# MCXA133 register map
Vendor: nxp.com; File version: 1.0
CPU: CM33 r2p0, little endian, no MPU, no FPU, VTOR, 3 interrupt priority bits
Registers are 32-bit, read-write, reset 0x0 unless marked. A register's access mark holds for its fields unless they carry their own. Offsets are from the block's base; [hi:lo] are bit positions; 'fields as' and 'values as' point back to an identical list.

## SPC0 — SPC
Base 0x40090000
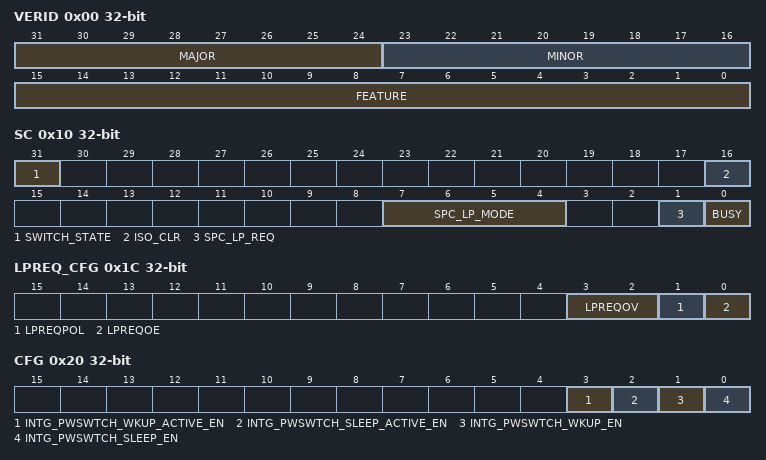
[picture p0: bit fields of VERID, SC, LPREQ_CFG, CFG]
0x00 VERID ro — Version ID
  [31:24] MAJOR — Major Version Number
  [23:16] MINOR — Minor Version Number
  [15:0] FEATURE — Feature Specification Number
    0=STANDARD (Standard features)
0x10 SC — Status Control
  [31] SWITCH_STATE ro — Power Switch State
    0=OFF; 1=ON
  [16] ISO_CLR write-1-clears — Isolation Clear Flags
  [7:4] SPC_LP_MODE ro — Power Domain Low-Power Mode Request
    0=MODE0 (Sleep mode with system clock running); 1=MODE1 (DSLEEP with system clock off); 2=MODE2 (PDOWN with system clock off); 8=MODE8 (DPDOWN with system clock off)
  [1] SPC_LP_REQ write-1-clears — SPC Power Mode Configuration Status Flag
    on read: 0=ACTIVE (SPC is in Active mode; the ACTIVE_CFG register has control); 1=LOW_POWER (All power domains requested low-power mode; SPC entered a low-power state; power-mode configuration based on the LP_CFG register)
  [0] BUSY ro — SPC Busy Status Flag
    0=BUSY_NO (Not busy); 1=BUSY_YES
0x1C LPREQ_CFG — Low-Power Request Configuration
  [3:2] LPREQOV — Low-Power Request Output Override
    0=FORCE_NO (Not forced); 2=FORCE_LOW (Forced low (ignore LPREQPOL settings)); 3=FORCE_HIGH (Forced high (ignore LPREQPOL settings))
  [1] LPREQPOL — Low-Power Request Output Pin Polarity Control
    0=HIGH; 1=LOW
  [0] LPREQOE — Low-Power Request Output Enable
    0=DISABLE; 1=ENABLE
0x20 CFG — SPC Configuration
  [all] fields
    0=DISABLE; 1=ENABLE
  [3] INTG_PWSWTCH_WKUP_ACTIVE_EN — Integrated Power Switch Wake-up Enable
  [2] INTG_PWSWTCH_SLEEP_ACTIVE_EN — Integrated Power Switch Active Enable
  [1] INTG_PWSWTCH_WKUP_EN — Integrated Power Switch Wake-up Enable
  [0] INTG_PWSWTCH_SLEEP_EN — Integrated Power Switch Sleep Enable
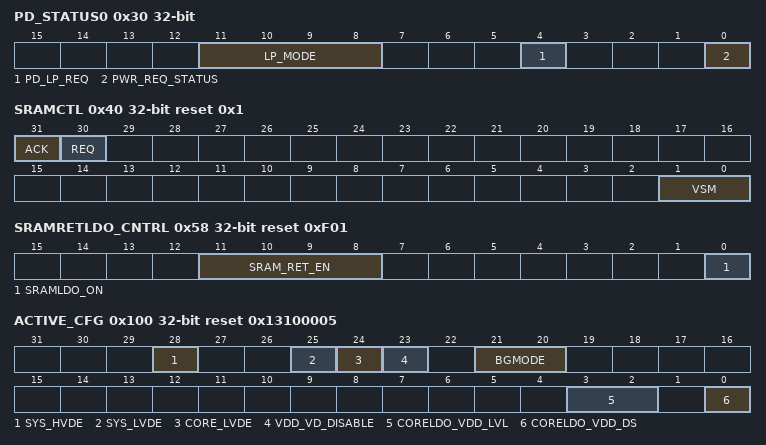
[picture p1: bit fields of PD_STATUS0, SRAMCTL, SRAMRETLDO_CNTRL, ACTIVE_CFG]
0x30 PD_STATUS0 — SPC Power Domain Mode Status
  [11:8] LP_MODE ro — Power Domain Low Power Mode Request
    0=MODE0 (SLEEP with system clock running); 1=MODE1 (DSLEEP with system clock off); 2=MODE2 (PDOWN with system clock off); 8=MODE8 (DPDOWN with system clock off)
  [4] PD_LP_REQ write-1-clears — Power Domain Low Power Request Flag
    0=REQ_NO (Did not request); 1=REQ_YES (Requested)
  [0] PWR_REQ_STATUS ro — Power Request Status Flag
    0=REQ_NO (Did not request); 1=REQ_YES (Requested)
0x40 SRAMCTL reset 0x1 — SRAM Control
  [31] ACK ro — SRAM Voltage Update Request Acknowledge
    0=ACK_NO (Not acknowledged); 1=ACK_YES (Acknowledged)
  [30] REQ — SRAM Voltage Update Request
    0=REQ_NO (Do not request); 1=REQ_YES (Request)
  [1:0] VSM — Voltage Select Margin
    1=1.0 V; 2=1.1 V; 3=SRAM configured for 1.2 V operation
0x54 SRAMRETLDO_REFTRIM reset 0x17 — SRAM Retention Reference Trim
  [4:0] REFTRIM — Reference Trim. Voltage range is around 0.48V - 0.85V. Trim step is 12 mV.
0x58 SRAMRETLDO_CNTRL reset 0xF01 — SRAM Retention LDO Control
  [11:8] SRAM_RET_EN — SRAM Retention
  [0] SRAMLDO_ON — SRAM LDO Regulator Enable
    0=DISABLE; 1=ENABLE
0x100 ACTIVE_CFG reset 0x13100005 — Active Power Mode Configuration
  [28] SYS_HVDE — System High-Voltage Detection Enable
    0=DISABLE; 1=ENABLE
  [25] SYS_LVDE — System Low-Voltage Detection Enable
    0=DISABLE; 1=ENABLE
  [24] CORE_LVDE — Core Low-Voltage Detection Enable
    0=DISABLE; 1=ENABLE
  [23] VDD_VD_DISABLE — VDD Voltage Detect Disable
    0=ENABLE; 1=DISABLE
  [21:20] BGMODE — Bandgap Mode
    0=Bandgap disabled; 1=Bandgap enabled, buffer disabled; 2=Bandgap enabled, buffer enabled
  [3:2] CORELDO_VDD_LVL — LDO_CORE VDD Regulator Voltage Level
    1=MID (Regulate to mid voltage (1.0 V)); 2=NORMAL (Regulate to normal voltage (1.1 V)); 3=OVER (Regulate to overdrive voltage (1.15 V))
  [0] CORELDO_VDD_DS — LDO_CORE VDD Drive Strength
    0=LOW; 1=NORMAL
0x104 ACTIVE_CFG1 reset 0x2 — Active Power Mode Configuration 1
  [31:0] SOC_CNTRL — Active Config Chip Control
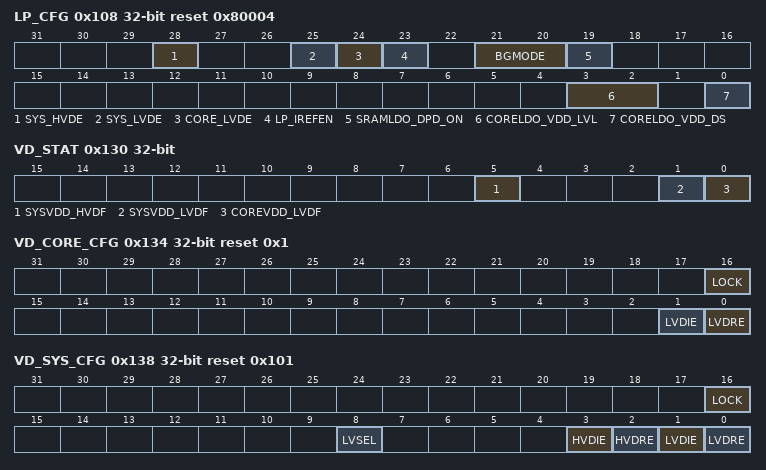
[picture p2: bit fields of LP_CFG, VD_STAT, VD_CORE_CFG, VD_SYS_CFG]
0x108 LP_CFG reset 0x80004 — Low-Power Mode Configuration
  [28] SYS_HVDE — System High Voltage Detect Enable
    0=DISABLE; 1=ENABLE
  [25] SYS_LVDE — System Low Voltage Detect Enable
    0=DISABLE; 1=ENABLE
  [24] CORE_LVDE — Core Low Voltage Detect Enable
    0=DISABLE; 1=ENABLE
  [23] LP_IREFEN — Low-Power IREF Enable
    0=DISABLE (Disable for power saving in Deep Power Down mode); 1=ENABLE
  [21:20] BGMODE — Bandgap Mode
    values as ACTIVE_CFG.BGMODE
  [19] SRAMLDO_DPD_ON — SRAM_LDO Deep Power Low Power IREF Enable
    0=DISABLED (Low Power IREF is disabled for power saving in Deep Power Down mode); 1=ENABLED (Low Power IREF is enabled)
  [3:2] CORELDO_VDD_LVL — LDO_CORE VDD Regulator Voltage Level
    1=MID (Mid voltage (1.0 V)); 2=NORMAL (Normal voltage (1.1 V)); 3=OVER (Overdrive voltage (1.15 V))
  [0] CORELDO_VDD_DS — LDO_CORE VDD Drive Strength
    0=LOW; 1=NORMAL
0x10C LP_CFG1 reset 0x2 — Low Power Mode Configuration 1
  [31:0] SOC_CNTRL — Low-Power Configuration Chip Control
0x120 LPWKUP_DELAY — Low Power Wake-Up Delay
  [15:0] LPWKUP_DELAY — Low-Power Wake-Up Delay
0x124 ACTIVE_VDELAY reset 0xC8 — Active Voltage Trim Delay
  [15:0] ACTIVE_VDELAY — Active Voltage Delay
0x130 VD_STAT write-1-clears — Voltage Detect Status
  [all] fields
    on read: 0=EVENT_NO (Event not detected); 1=EVENT_YES (Event detected)
  [5] SYSVDD_HVDF write-1-clears — System HVD Flag
  [1] SYSVDD_LVDF write-1-clears — System Low-Voltage Detect Flag
  [0] COREVDD_LVDF write-1-clears — Core Low-Voltage Detect Flag
0x134 VD_CORE_CFG reset 0x1 — Core Voltage Detect Configuration
  [16] LOCK — Core Voltage Detect Reset Enable Lock
    0=ALLOW; 1=DENY
  [1] LVDIE — Core LVD Interrupt Enable
    0=DISABLE; 1=ENABLE
  [0] LVDRE — Core LVD Reset Enable
    0=DISABLE; 1=ENABLE
0x138 VD_SYS_CFG reset 0x101 — System Voltage Detect Configuration
  [16] LOCK — System Voltage Detect Reset Enable Lock
    0=ALLOW; 1=DENY
  [8] LVSEL — System Low-Voltage Level Select
    0=NORMAL; 1=SAFE
  [3] HVDIE — System HVD Interrupt Enable
    0=DISABLE; 1=ENABLE
  [2] HVDRE — System HVD Reset Enable
    0=DISABLE; 1=ENABLE
  [1] LVDIE — System LVD Interrupt Enable
    0=DISABLE; 1=ENABLE
  [0] LVDRE — System LVD Reset Enable
    0=DISABLE; 1=ENABLE
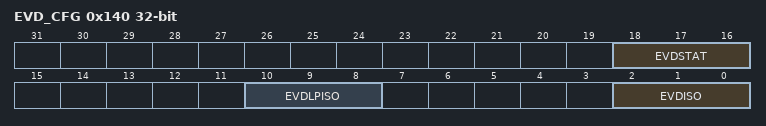
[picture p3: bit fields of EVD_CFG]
0x140 EVD_CFG — External Voltage Domain Configuration
  [18:16] EVDSTAT ro — External Voltage Domain Status
  [10:8] EVDLPISO — External Voltage Domain Low-Power Isolation
  [2:0] EVDISO — External Voltage Domain Isolation
0x300 CORELDO_CFG ro — LDO_CORE Configuration
